# AC7842x register map
Vendor: AutoChips; Series: AC78; File version: 1.0
CPU: CM4 r0p1, little endian, MPU, FPU, VTOR, 4 interrupt priority bits
Registers are 32-bit, read-write, reset 0x0 unless marked. A register's access mark holds for its fields unless they carry their own. Offsets are from the block's base; [hi:lo] are bit positions; {n}, {i} and the like mark numbered series.

## UART0 — Universal Asynchronous Receiver/Transmitter
Base 0x40018000
Same registers: UART1 0x40018200, UART2 0x40018400, UART3 0x40018600
0x00 RBR reset not defined — RX/TX Data Register
  [8:0] RBR_THR
0x04 DIV_L reset 0x1 (reset mask 0x0) — Divisor low 8 bits register
  [7:0] DIV_L — UART baud rate divisor low 8 bits
0x08 DIV_H reset not defined — Divisor high 8 bits register
  [7:0] DIV_H — UART baud rate divisor high 8 bits
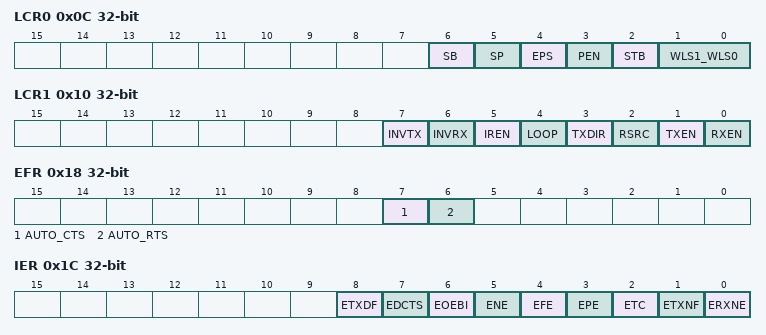
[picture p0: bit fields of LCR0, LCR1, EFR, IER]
0x0C LCR0 reset not defined — UART control register 0
  [6] SB — Sets up break
    0=No effect; 1=SOUT signal is forced into the 0 state
  [5] SP — stick parity
  [4] EPS — Even parity select
    0=Odd parity; 1=Even parity
  [3] PEN — Parity enable Bit
    0=Parity is disabled; 1=Parity is enabled
  [2] STB — Number of stop bits
    0=One stop bit; 1=Two stop bits
  [1:0] WLS1_WLS0 — UART word length select
    0=7_BIT (7 BITS); 1=8_BIT (8 BITS); 2=9_BIT (9 BITS)
0x10 LCR1 reset not defined — UART control register 1
  [7] INVTX — Transmit Data Inversion
    0=Transmit data not inverted; 1=Transmit data inverted
  [6] INVRX — Receive Data Inversion
    0=Receive data not inverted; 1=Receive data inverted
  [5] IREN — Infrared enable
    0=IR disabled; 1=IR enabled
  [4] LOOP — Loop mode enable
    0=Normal operation; 1=Loop mode or single-wire mode
  [3] TXDIR — TX Direction
    0=TXD is an input in single-wire mode; 1=TXD is an output in single-wire mode
  [2] RSRC — Receiver Source Select
    0=LOOPS mode; 1=Single-wire mode
  [1] TXEN — UART Transmitter enable
    0=Disabled; 1=Enabled
  [0] RXEN — UART receiver enable
    0=Disabled; 1=Enabled
0x14 FCR reset not defined — FIFO Control Register
  [0] FIFOE — RX and TX FIFO enable
    0=Disable; 1=Enable
0x18 EFR reset not defined — hardware flow control register
  [7] AUTO_CTS — hardware transmiison flow control enable/disable bit
    0=Disable; 1=Enable
  [6] AUTO_RTS — hardware reception flow control enable/disable bit
    0=Disable; 1=Enable
0x1C IER reset not defined — Interrupt Enable register
  [all] fields
    0=Disable; 1=Enable
  [8] ETXDF — TX data register or TX FIFO full interrupt enable bit
  [7] EDCTS — CTS_n changing interrupt enable bit
  [6] EOEBI — overflow error or break error interrupt enable bit
  [5] ENE — noise error interrupt enable bit
  [4] EFE — overflow or frame error interrupt enable bit
  [3] EPE — parity error interrupt enable bit
  [2] ETC — transmitting completed interrupt enable bit
  [1] ETXNF — transmitting data not full interrupt enable bit
  [0] ERXNE — receiving data not empty interrupt enable bit
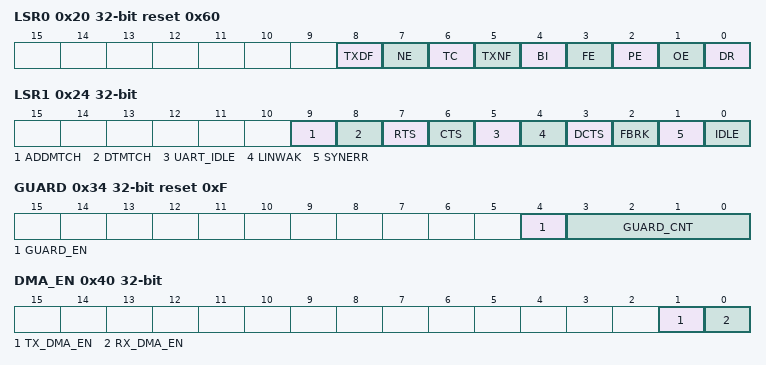
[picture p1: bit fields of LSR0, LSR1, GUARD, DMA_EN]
0x20 LSR0 reset 0x60 (reset mask 0x0) — Line Status Register 0
  [8] TXDF — TX register or TX FIFO full flag
    0=TX data register is empty or TX FIFO if not full; 1=TX data register or TX FIFO is full
  [7] NE — noise error flag
    0=No noise error; 1=Noise error
  [6] TC — Transmitting finished flag
    0=Transmitter has not finished the data shifting; 1=Transmitter has finished the data shifting
  [5] TXNF — TX data register empty or TX FIFO not full flag
    0=TX data register or TX FIFO is full; 1=TX data register is empty or TX FIFO if not full
  [4] BI — break error flag
    0=No break error; 1=Break error
  [3] FE — frame error flag
    0=No frame error; 1=Frame error
  [2] PE — parity error flag
    0=No parity error; 1=Parity error
  [1] OE — overrun error flag
    0=No overrun; 1=RX overrun
  [0] DR — Data ready flag
    0=RX data register or FIFO is empty; 1=RX data register or FIFO is not empty
0x24 LSR1 reset not defined — Line Status Register 1
  [9] ADDMTCH — Address match
    0=No match; 1=Match
  [8] DTMTCH — Data match
    0=No match; 1=Match
  [7] RTS — Hardware flow status - RTS
    0=RX buffer is full; 1=RX buffer is not full
  [6] CTS — Hardware flow status - CTS
    0=Other device RX buffer is full; 1=Other device RX buffer is not full
  [5] UART_IDLE
    0=UART is at operation; 1=UART is not at operation
  [4] LINWAK — LIN wakeup flag
    0=No LIN is wakeup; 1=LIN is wakeup
  [3] DCTS — Pin CTS_n signal changing flag
    0=No CTS_n signal changed; 1=CTS_n signal changed
  [2] FBRK — LIN break occur flag
    0=No LIN break detected; 1=LIN break detected
  [1] SYNERR — LIN sync field error flag
    0=No sync field error; 1=Sync field error
  [0] IDLE — IDLE flag
    0=No idle line detected; 1=Idle line was detected
0x28 SMP_CNT reset not defined — UART sample counter register
  [1:0] SMP_CNT — UART sample counter
    0=16; 1=8; 2=4
0x2C ADDR reset not defined — UART match address register
  [8:0] ADDR — UART match address
0x30 DATA reset not defined — UART match data register
  [8:0] DATA — UART match data
0x34 GUARD reset 0xF (reset mask 0x0) — UART guard time register
  [4] GUARD_EN — Guard interval time added enabling signal
    0=Disable; 1=Enable
  [3:0] GUARD_CNT — Guard interval count value
0x3C SLEEP_EN reset not defined — UART sleep enable register
  [0] SLEEP_EN — UART sleep function enable bit
    0=Disable; 1=Enable
0x40 DMA_EN reset not defined — UART DMA enable register
  [1] TX_DMA_EN — UART TX DMA enable bit
    0=Disable; 1=Enable
  [0] RX_DMA_EN — UART RX DMA enable bit
    0=Disable; 1=Enable
0x44 DIV_FRAC reset not defined — Uart Fractional Divider Address
  [4:0] DIV_FRAC — UART fractional divider
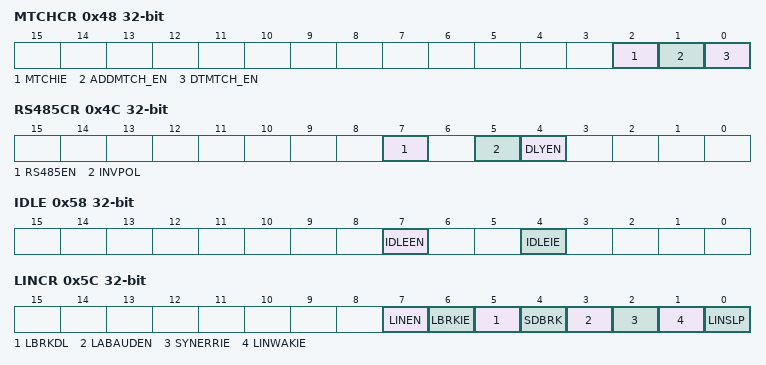
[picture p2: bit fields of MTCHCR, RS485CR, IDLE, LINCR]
0x48 MTCHCR reset not defined — Uart match fucntion enable
  [2] MTCHIE — UART match interrupt enable
  [1] ADDMTCH_EN — UART address filter enable
  [0] DTMTCH_EN — UART data match enable
0x4C RS485CR reset not defined — Uart RS485 control register
  [7] RS485EN — RS485 mode enable bit
    0=Disable RS485; 1=Enable RS485
  [5] INVPOL — inverse the polarity of rts_n
    0=Not inverse RTS_n; 1=Inverse RTS_n
  [4] DLYEN — Delay insert between the last stop bit and rts_n or dtr_n de-assertion
    0=Disable delay; 1=Enable delay
0x54 CNTR reset not defined — Uart Counter time delay in RS485 mode
  [7:0] CNTR
0x58 IDLE reset not defined — Uart IDLE register
  [7] IDLEEN — Idle detect enable
    0=Disable; 1=Enable
  [4] IDLEIE — IDLE interrupt enable bit
    0=Disable; 1=Enable
0x5C LINCR reset not defined — LIN Control register
  [7] LINEN — LIN mode enable/disable
    0=Disable; 1=Enable
  [6] LBRKIE — LIN break detection interrupt enable/disable
    0=Disable; 1=Enable
  [5] LBRKDL — LIN break detect threshold
    0=10 bits; 1=11 bits
  [4] SDBRK — LIN transfer break field enable/disable
    0=Disable; 1=Enable
  [3] LABAUDEN — LIN automatic baudrate synch enable/disable
    0=Disable; 1=Enable
  [2] SYNERRIE — LIN synch byte error interrupt enable/disable
    0=Disable; 1=Enable
  [1] LINWAKIE — LIN wakeup interrupt enable/disable
    0=Disable; 1=Enable
  [0] LINSLP — LIN sleep mode
    0=LIN is normal mode; 1=LIN is sleep mode
0x60 BRKLGH reset not defined — LIN Break Length Select Register
  [3:0] BRKLGH — Break length
    {v}={v+13} bits (v=0..15)
0x64 PMIN0 reset not defined — IrDA mode pulse minimum pulse
  [7:0] PMIN0
0x68 PMIN1 reset not defined — IrDA mode pulse minimum pulse
  [7:0] PMIN1
0x6C PWDTH reset not defined — IrDA mode pulse width for transmit
  [2:0] PWDTH — IrDA mode transmit pulse duration
    0=3/16 of normal pulse duration; 1=1/16 of normal pulse duration; 2=2/16 of normal pulse duration; 3=4/16 of normal pulse duration; 0b1XX=3/16 of normal pulse duration
